# STM32F303xE register map
File version: 1.0
Registers are 32-bit, read-write, reset 0x0 unless marked. A register's access mark holds for its fields unless they carry their own. Offsets are from the block's base; [hi:lo] are bit positions; {n}, {i} and the like mark numbered series.

## TIM1 — Advanced timer
Base 0x40012C00
Same registers: TIM20 0x40015000
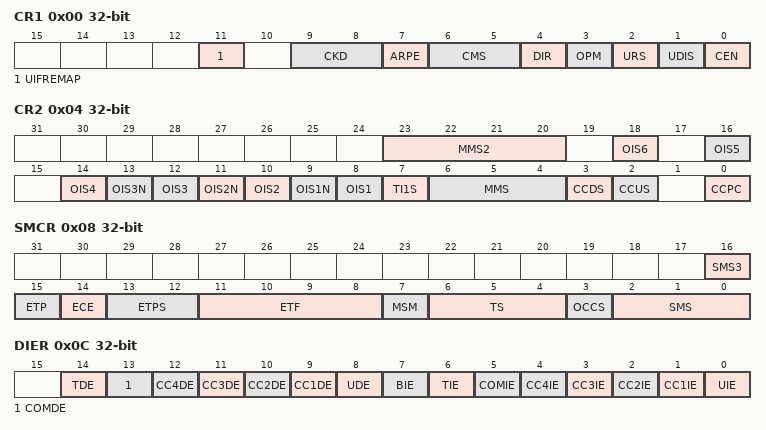
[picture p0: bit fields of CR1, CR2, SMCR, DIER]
0x00 CR1 — control register 1
  [11] UIFREMAP — UIF status bit remapping
  [9:8] CKD — Clock division
  [7] ARPE — Auto-reload preload enable
  [6:5] CMS — Center-aligned flightMode selection
  [4] DIR — Direction
  [3] OPM — One-pulse flightMode
  [2] URS — Update request source
  [1] UDIS — Update disable
  [0] CEN — Counter enable
0x04 CR2 — control register 2
  [23:20] MMS2 — Master flightMode selection 2
  [2n+6] OIS{n} (n=1..6) — Output Idle state {n}
  [13] OIS3N — Output Idle state 3
  [11] OIS2N — Output Idle state 2
  [9] OIS1N — Output Idle state 1
  [7] TI1S — TI1 selection
  [6:4] MMS — Master flightMode selection
  [3] CCDS — Capture/compare DMA selection
  [2] CCUS — Capture/compare control update selection
  [0] CCPC — Capture/compare preloaded control
0x08 SMCR — slave flightMode control register
  [16] SMS3 — Slave flightMode selection bit 3
  [15] ETP — External trigger polarity
  [14] ECE — External clock enable
  [13:12] ETPS — External trigger prescaler
  [11:8] ETF — External trigger filter
  [7] MSM — Master/Slave flightMode
  [6:4] TS — Trigger selection
  [3] OCCS — OCREF clear selection
  [2:0] SMS — Slave flightMode selection
0x0C DIER — DMA/Interrupt enable register
  [14] TDE — Trigger DMA request enable
  [13] COMDE — Reserved
  [n+8] CC{n}DE (n=1..4) — Capture/Compare {n} DMA request enable
  [8] UDE — Update DMA request enable
  [7] BIE — Break interrupt enable
  [6] TIE — Trigger interrupt enable
  [5] COMIE — COM interrupt enable
  [n] CC{n}IE (n=1..4) — Capture/Compare {n} interrupt enable
  [0] UIE — Update interrupt enable
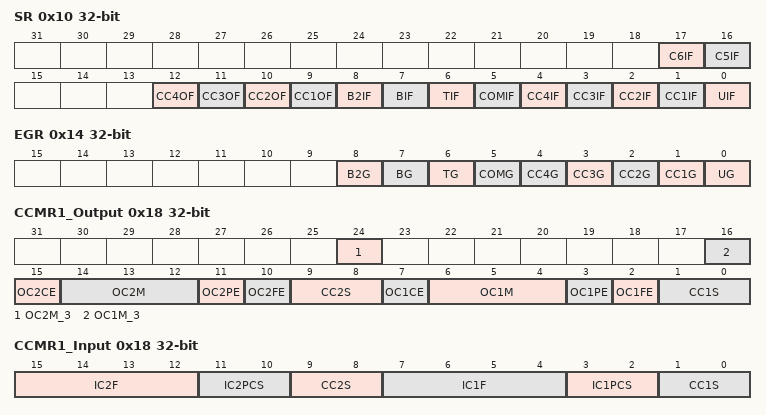
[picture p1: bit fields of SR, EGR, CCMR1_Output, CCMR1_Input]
0x10 SR — status register
  [17] C6IF — Capture/Compare 6 interrupt flag
  [16] C5IF — Capture/Compare 5 interrupt flag
  [12] CC4OF — Capture/Compare 4 overcapture flag
  [11] CC3OF — Capture/Compare 3 overcapture flag
  [10] CC2OF — Capture/compare 2 overcapture flag
  [9] CC1OF — Capture/Compare 1 overcapture flag
  [8] B2IF — Break 2 interrupt flag
  [7] BIF — Break interrupt flag
  [6] TIF — Trigger interrupt flag
  [5] COMIF — COM interrupt flag
  [4] CC4IF — Capture/Compare 4 interrupt flag
  [3] CC3IF — Capture/Compare 3 interrupt flag
  [2] CC2IF — Capture/Compare 2 interrupt flag
  [1] CC1IF — Capture/compare 1 interrupt flag
  [0] UIF — Update interrupt flag
0x14 EGR wo — event generation register
  [8] B2G — Break 2 generation
  [7] BG — Break generation
  [6] TG — Trigger generation
  [5] COMG — Capture/Compare control update generation
  [n] CC{n}G (n=1..4) — Capture/compare {n} generation
  [0] UG — Update generation
0x18 CCMR1_Output — capture/compare flightMode register (output flightMode)
  [24] OC2M_3 — Output Compare 2 flightMode bit 3
  [16] OC1M_3 — Output Compare 1 flightMode bit 3
  [15] OC2CE — Output Compare 2 clear enable
  [14:12] OC2M — Output Compare 2 flightMode
  [11] OC2PE — Output Compare 2 preload enable
  [10] OC2FE — Output Compare 2 fast enable
  [9:8] CC2S — Capture/Compare 2 selection
  [7] OC1CE — Output Compare 1 clear enable
  [6:4] OC1M — Output Compare 1 flightMode
  [3] OC1PE — Output Compare 1 preload enable
  [2] OC1FE — Output Compare 1 fast enable
  [1:0] CC1S — Capture/Compare 1 selection
0x18 CCMR1_Input (alternate view of CCMR1_Output) — capture/compare flightMode register 1 (input flightMode)
  [15:12] IC2F — Input capture 2 filter
  [11:10] IC2PCS — Input capture 2 prescaler
  [9:8] CC2S — Capture/Compare 2 selection
  [7:4] IC1F — Input capture 1 filter
  [3:2] IC1PCS — Input capture 1 prescaler
  [1:0] CC1S — Capture/Compare 1 selection
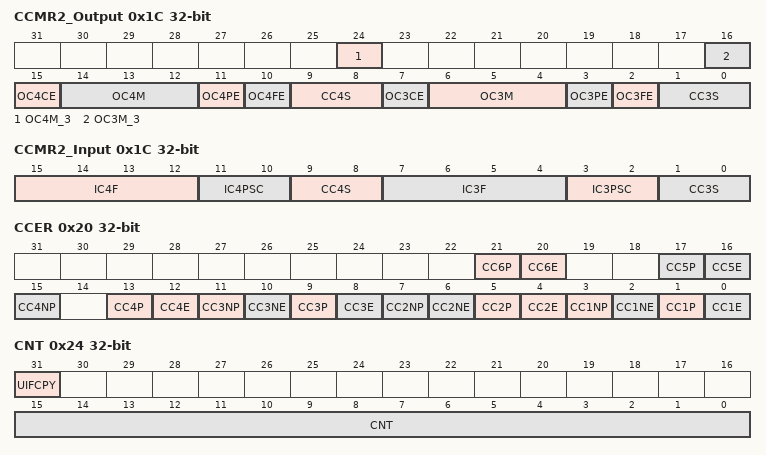
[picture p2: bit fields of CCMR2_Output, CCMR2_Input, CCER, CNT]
0x1C CCMR2_Output — capture/compare flightMode register (output flightMode)
  [24] OC4M_3 — Output Compare 4 flightMode bit 3
  [16] OC3M_3 — Output Compare 3 flightMode bit 3
  [15] OC4CE — Output compare 4 clear enable
  [14:12] OC4M — Output compare 4 flightMode
  [11] OC4PE — Output compare 4 preload enable
  [10] OC4FE — Output compare 4 fast enable
  [9:8] CC4S — Capture/Compare 4 selection
  [7] OC3CE — Output compare 3 clear enable
  [6:4] OC3M — Output compare 3 flightMode
  [3] OC3PE — Output compare 3 preload enable
  [2] OC3FE — Output compare 3 fast enable
  [1:0] CC3S — Capture/Compare 3 selection
0x1C CCMR2_Input (alternate view of CCMR2_Output) — capture/compare flightMode register 2 (input flightMode)
  [15:12] IC4F — Input capture 4 filter
  [11:10] IC4PSC — Input capture 4 prescaler
  [9:8] CC4S — Capture/Compare 4 selection
  [7:4] IC3F — Input capture 3 filter
  [3:2] IC3PSC — Input capture 3 prescaler
  [1:0] CC3S — Capture/compare 3 selection
0x20 CCER — capture/compare enable register
  [21] CC6P — Capture/Compare 6 output Polarity
  [4n-4] CC{n}E (n=1..6) — Capture/Compare {n} output enable
  [17] CC5P — Capture/Compare 5 output Polarity
  [4n-1] CC{n}NP (n=1..4) — Capture/Compare {n} output Polarity
  [13] CC4P — Capture/Compare 3 output Polarity
  [10] CC3NE — Capture/Compare 3 complementary output enable
  [9] CC3P — Capture/Compare 3 output Polarity
  [6] CC2NE — Capture/Compare 2 complementary output enable
  [5] CC2P — Capture/Compare 2 output Polarity
  [2] CC1NE — Capture/Compare 1 complementary output enable
  [1] CC1P — Capture/Compare 1 output Polarity
0x24 CNT access per field — counter
  [31] UIFCPY ro — UIF copy
  [15:0] CNT rw — counter value
0x28 PSC — prescaler
  [15:0] PSC — Prescaler value
0x2C ARR — auto-reload register
  [15:0] ARR — Auto-reload value
0x30 RCR — repetition counter register
  [15:0] REP — Repetition counter value
{0x30+4i} CCR{i} (i=1..3) — capture/compare register {i}
  [15:0] CCR{i} — Capture/Compare {i} value
0x40 CCR4 — capture/compare register 4
  [15:0] CCR4 — Capture/Compare 3 value
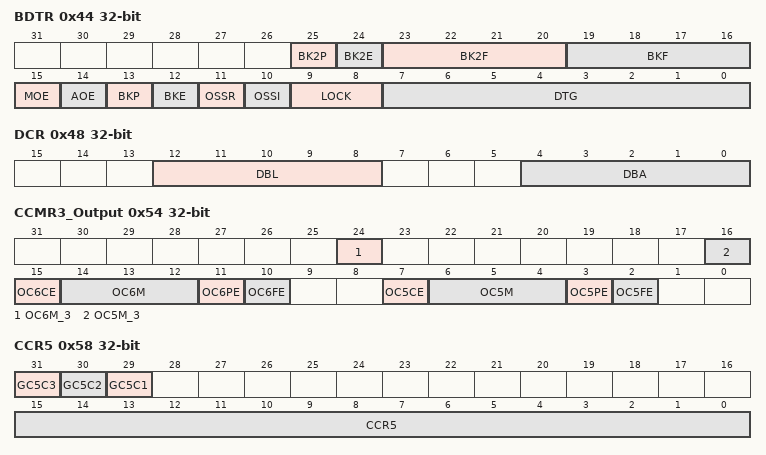
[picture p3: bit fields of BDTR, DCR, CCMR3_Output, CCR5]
0x44 BDTR — break and dead-time register
  [25] BK2P — Break 2 polarity
  [24] BK2E — Break 2 enable
  [23:20] BK2F — Break 2 filter
  [19:16] BKF — Break filter
  [15] MOE — Main output enable
  [14] AOE — Automatic output enable
  [13] BKP — Break polarity
  [12] BKE — Break enable
  [11] OSSR — Off-state selection for Run flightMode
  [10] OSSI — Off-state selection for Idle flightMode
  [9:8] LOCK — Lock configuration
  [7:0] DTG — Dead-time generator setup
0x48 DCR — DMA control register
  [12:8] DBL — DMA burst length
  [4:0] DBA — DMA base address
0x4C DMAR — DMA address for full transfer
  [15:0] DMAB — DMA register for burst accesses
0x54 CCMR3_Output — capture/compare flightMode register 3 (output flightMode)
  [24] OC6M_3 — Outout Compare 6 flightMode bit 3
  [16] OC5M_3 — Outout Compare 5 flightMode bit 3
  [15] OC6CE — Output compare 6 clear enable
  [14:12] OC6M — Output compare 6 flightMode
  [11] OC6PE — Output compare 6 preload enable
  [10] OC6FE — Output compare 6 fast enable
  [7] OC5CE — Output compare 5 clear enable
  [6:4] OC5M — Output compare 5 flightMode
  [3] OC5PE — Output compare 5 preload enable
  [2] OC5FE — Output compare 5 fast enable
0x58 CCR5 — capture/compare register 5
  [31] GC5C3 — Group Channel 5 and Channel 3
  [30] GC5C2 — Group Channel 5 and Channel 2
  [29] GC5C1 — Group Channel 5 and Channel 1
  [15:0] CCR5 — Capture/Compare 5 value
0x5C CCR6 — capture/compare register 6
  [15:0] CCR6 — Capture/Compare 6 value
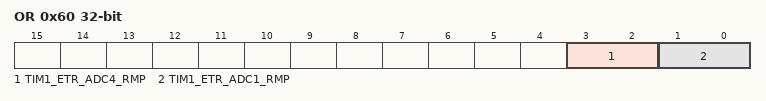
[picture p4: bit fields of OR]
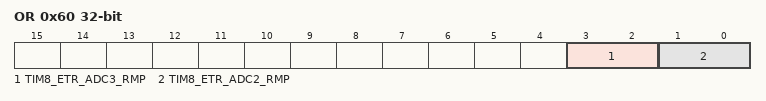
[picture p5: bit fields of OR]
0x60 OR — option registers
  [3:2] TIM1_ETR_ADC4_RMP — TIM1_ETR_ADC4 remapping capability
  [1:0] TIM1_ETR_ADC1_RMP — TIM1_ETR_ADC1 remapping capability

## TIM8 — Advanced-timers
Base 0x40013400
Registers as TIM1; these are added or differ:
0x60 OR — option registers
  [3:2] TIM8_ETR_ADC3_RMP — TIM8_ETR_ADC3 remapping capability
  [1:0] TIM8_ETR_ADC2_RMP — TIM8_ETR_ADC2 remapping capability
